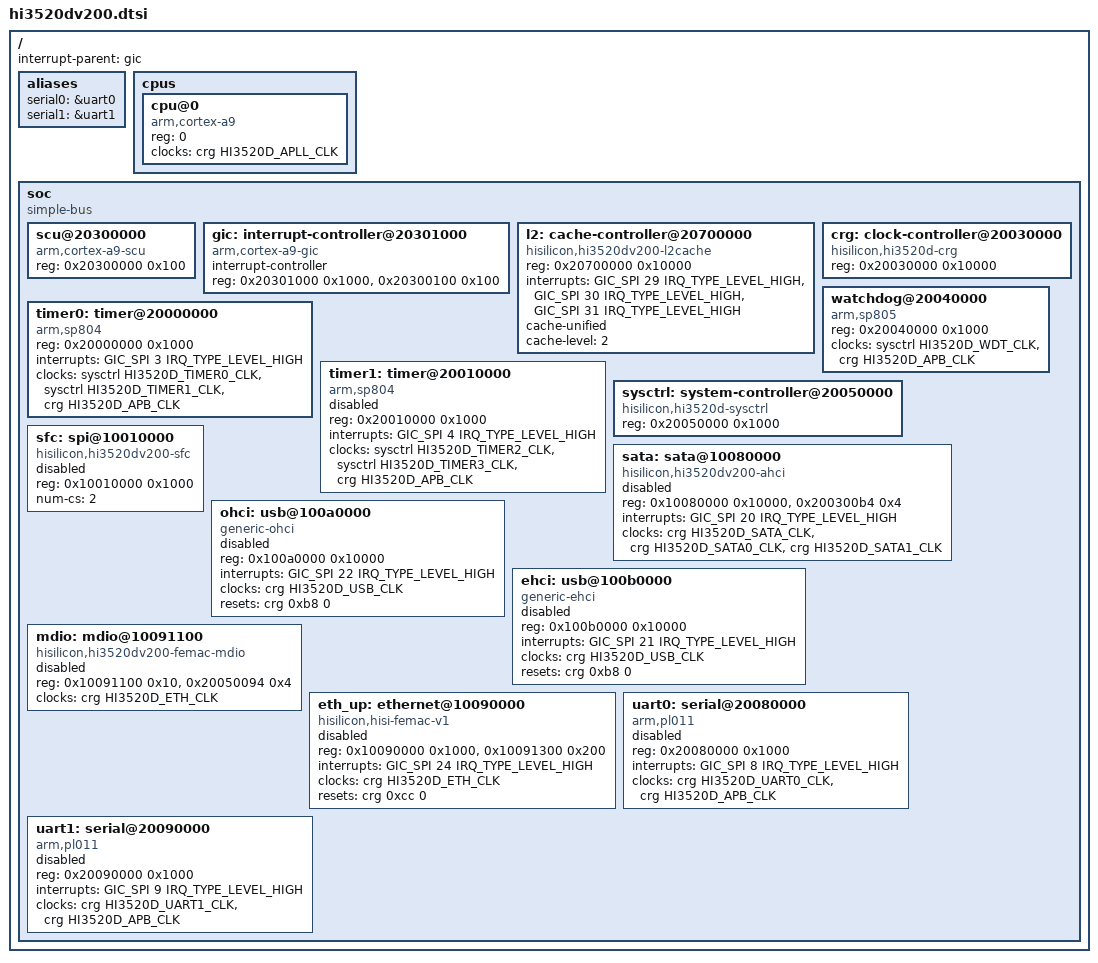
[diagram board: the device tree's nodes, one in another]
// SPDX-License-Identifier: (GPL-2.0-or-later OR MIT)
/*
 * HiSilicon Hi3520DV200 NVR/DVR SoC: a single Cortex-A9 with GIC, SP804
 * timers and a HiSilicon (not PL310) L2 cache controller.
 *
 * Addresses and interrupt numbers follow the vendor 3.0.8 BSP
 * (arch/arm/mach-hi3520d: platform.h, irqs.h). There is no clock driver
 * The clocks and resets come from the CRG and the system controller. The
 * SP804 timers and the SP805 take their count clock from the system
 * controller's select (3 MHz or the APB clock) and the PL011s theirs from
 * PERI_CRG57; both rates are read back from the hardware, so no bootloader
 * has to be assumed.
 */

#include <dt-bindings/clock/hi3520d-clock.h>
#include <dt-bindings/interrupt-controller/arm-gic.h>
#include <dt-bindings/interrupt-controller/irq.h>

/ {
	#address-cells = <1>;
	#size-cells = <1>;
	interrupt-parent = <&gic>;

	aliases {
		serial0 = &uart0;
		serial1 = &uart1;
	};

	cpus {
		#address-cells = <1>;
		#size-cells = <0>;

		cpu@0 {
			device_type = "cpu";
			compatible = "arm,cortex-a9";
			reg = <0>;
			clocks = <&crg HI3520D_APLL_CLK>;
		};
	};

	soc {
		compatible = "simple-bus";
		#address-cells = <1>;
		#size-cells = <1>;
		ranges;

		scu@20300000 {
			compatible = "arm,cortex-a9-scu";
			reg = <0x20300000 0x100>;
		};

		gic: interrupt-controller@20301000 {
			compatible = "arm,cortex-a9-gic";
			#interrupt-cells = <3>;
			#address-cells = <0>;
			interrupt-controller;
			reg = <0x20301000 0x1000>, <0x20300100 0x100>;
		};

		/*
		 * HiSilicon's own L2 controller ("hil2v200"), not a PL310: its
		 * ID register reads 0. 128 KB, 8 ways, 32-byte lines.
		 */
		l2: cache-controller@20700000 {
			compatible = "hisilicon,hi3520dv200-l2cache";
			reg = <0x20700000 0x10000>;
			interrupts = <GIC_SPI 29 IRQ_TYPE_LEVEL_HIGH>,
				     <GIC_SPI 30 IRQ_TYPE_LEVEL_HIGH>,
				     <GIC_SPI 31 IRQ_TYPE_LEVEL_HIGH>;
			cache-unified;
			cache-level = <2>;
		};

		timer0: timer@20000000 {
			compatible = "arm,sp804", "arm,primecell";
			reg = <0x20000000 0x1000>;
			interrupts = <GIC_SPI 3 IRQ_TYPE_LEVEL_HIGH>;
			clocks = <&sysctrl HI3520D_TIMER0_CLK>,
				 <&sysctrl HI3520D_TIMER1_CLK>,
				 <&crg HI3520D_APB_CLK>;
			clock-names = "timer0clk", "timer1clk", "apb_pclk";
		};

		timer1: timer@20010000 {
			compatible = "arm,sp804", "arm,primecell";
			reg = <0x20010000 0x1000>;
			interrupts = <GIC_SPI 4 IRQ_TYPE_LEVEL_HIGH>;
			clocks = <&sysctrl HI3520D_TIMER2_CLK>,
				 <&sysctrl HI3520D_TIMER3_CLK>,
				 <&crg HI3520D_APB_CLK>;
			clock-names = "timer0clk", "timer1clk", "apb_pclk";
			status = "disabled";
		};

		/* PERI_CRG0..: PLLs, bus clocks, peripheral clock gates and soft resets */
		crg: clock-controller@20030000 {
			compatible = "hisilicon,hi3520d-crg";
			reg = <0x20030000 0x10000>;
			#clock-cells = <1>;
			#reset-cells = <2>;
		};

		watchdog@20040000 {
			compatible = "arm,sp805", "arm,primecell";
			reg = <0x20040000 0x1000>;
			clocks = <&sysctrl HI3520D_WDT_CLK>, <&crg HI3520D_APB_CLK>;
			clock-names = "wdog_clk", "apb_pclk";
		};

		/* SC_CTRL: the SP804 and SP805 count clock selects */
		sysctrl: system-controller@20050000 {
			compatible = "hisilicon,hi3520d-sysctrl";
			reg = <0x20050000 0x1000>;
			#clock-cells = <1>;
		};

		/* SFC v350: the register layout of the v3xx SPI-NOR controller. */
		sfc: spi@10010000 {
			compatible = "hisilicon,hi3520dv200-sfc";
			reg = <0x10010000 0x1000>;
			num-cs = <2>;
			#address-cells = <1>;
			#size-cells = <0>;
			status = "disabled";
		};

		/*
		 * reg 1 is PERI_CRG45, the SATA clock/reset register: the glue
		 * still sets the resets and the PHY bring-up order itself, the
		 * clock gates are also held by the clocks below.
		 */
		sata: sata@10080000 {
			compatible = "hisilicon,hi3520dv200-ahci";
			reg = <0x10080000 0x10000>, <0x200300b4 0x4>;
			interrupts = <GIC_SPI 20 IRQ_TYPE_LEVEL_HIGH>;
			clocks = <&crg HI3520D_SATA_CLK>,
				 <&crg HI3520D_SATA0_CLK>,
				 <&crg HI3520D_SATA1_CLK>;
			status = "disabled";
		};

		/*
		 * USB 2.0 host: clock gate and AHB reset in PERI_CRG46. The PHY
		 * (PERI_USB 0x20050080) is still left to the boot loader.
		 */
		ohci: usb@100a0000 {
			compatible = "generic-ohci";
			reg = <0x100a0000 0x10000>;
			interrupts = <GIC_SPI 22 IRQ_TYPE_LEVEL_HIGH>;
			clocks = <&crg HI3520D_USB_CLK>;
			resets = <&crg 0xb8 0>;
			status = "disabled";
		};

		ehci: usb@100b0000 {
			compatible = "generic-ehci";
			reg = <0x100b0000 0x10000>;
			interrupts = <GIC_SPI 21 IRQ_TYPE_LEVEL_HIGH>;
			clocks = <&crg HI3520D_USB_CLK>;
			resets = <&crg 0xb8 0>;
			status = "disabled";
		};

		/*
		 * The "hieth-sf" switch-fabric MAC: two ports, up (0x0000) and
		 * down (+0x2000), sharing global registers at +0x1300 and an
		 * MDIO controller at +0x1100. The up port's registers and bits
		 * are those of hisi-femac, which drives it with the global block
		 * passed as its second region.
		 */
		mdio: mdio@10091100 {
			compatible = "hisilicon,hi3520dv200-femac-mdio",
				     "hisilicon,hisi-femac-mdio";
			/* MDIO, then the internal PHY control (SYS_CTRL PERI24) */
			reg = <0x10091100 0x10>, <0x20050094 0x4>;
			clocks = <&crg HI3520D_ETH_CLK>;
			clock-names = "mdio";
			#address-cells = <1>;
			#size-cells = <0>;
			status = "disabled";
		};

		eth_up: ethernet@10090000 {
			compatible = "hisilicon,hisi-femac-v1";
			reg = <0x10090000 0x1000>, <0x10091300 0x200>;
			interrupts = <GIC_SPI 24 IRQ_TYPE_LEVEL_HIGH>;
			clocks = <&crg HI3520D_ETH_CLK>;
			resets = <&crg 0xcc 0>;
			reset-names = "mac";
			status = "disabled";
		};

		uart0: serial@20080000 {
			compatible = "arm,pl011", "arm,primecell";
			reg = <0x20080000 0x1000>;
			interrupts = <GIC_SPI 8 IRQ_TYPE_LEVEL_HIGH>;
			clocks = <&crg HI3520D_UART0_CLK>, <&crg HI3520D_APB_CLK>;
			clock-names = "uartclk", "apb_pclk";
			status = "disabled";
		};

		uart1: serial@20090000 {
			compatible = "arm,pl011", "arm,primecell";
			reg = <0x20090000 0x1000>;
			interrupts = <GIC_SPI 9 IRQ_TYPE_LEVEL_HIGH>;
			clocks = <&crg HI3520D_UART1_CLK>, <&crg HI3520D_APB_CLK>;
			clock-names = "uartclk", "apb_pclk";
			status = "disabled";
		};
	};
};
